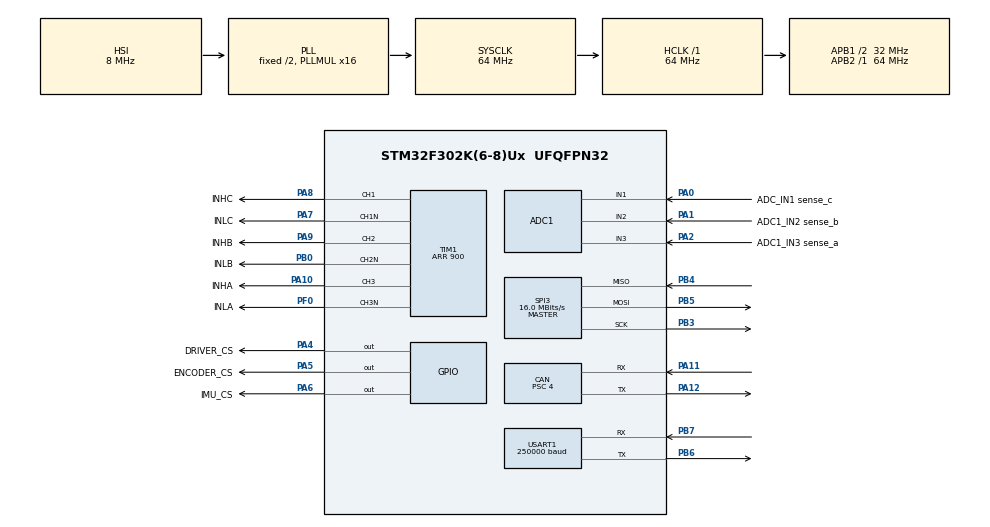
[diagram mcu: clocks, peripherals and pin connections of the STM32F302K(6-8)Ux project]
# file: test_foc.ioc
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ADC1.Channel-3\#ChannelRegularConversion=ADC_CHANNEL_1
ADC1.ContinuousConvMode=DISABLE
ADC1.DMAContinuousRequests=DISABLE
ADC1.EOCSelection=ADC_EOC_SEQ_CONV
ADC1.EnableInjectedConversion=ENABLE
ADC1.EnableRegularConversion=ENABLE
ADC1.ExternalTrigConv=ADC_SOFTWARE_START
ADC1.ExternalTrigConvEdge=ADC_EXTERNALTRIGCONVEDGE_RISING
ADC1.ExternalTrigInjecConv=ADC_EXTERNALTRIGINJECCONV_T1_CC4
ADC1.ExternalTrigInjecConvEdge=ADC_EXTERNALTRIGINJECCONV_EDGE_RISING
ADC1.InjNumberOfConversion=3
ADC1.InjectedChannel-4\#ChannelInjectedConversion=ADC_CHANNEL_1
ADC1.InjectedChannel-5\#ChannelInjectedConversion=ADC_CHANNEL_2
ADC1.InjectedChannel-6\#ChannelInjectedConversion=ADC_CHANNEL_3
ADC1.InjectedOffset-4\#ChannelInjectedConversion=0
ADC1.InjectedOffset-5\#ChannelInjectedConversion=0
ADC1.InjectedOffset-6\#ChannelInjectedConversion=0
ADC1.InjectedOffsetNumber-4\#ChannelInjectedConversion=ADC_OFFSET_NONE
ADC1.InjectedOffsetNumber-5\#ChannelInjectedConversion=ADC_OFFSET_NONE
ADC1.InjectedOffsetNumber-6\#ChannelInjectedConversion=ADC_OFFSET_NONE
ADC1.InjectedRank-4\#ChannelInjectedConversion=1
ADC1.InjectedRank-5\#ChannelInjectedConversion=2
ADC1.InjectedRank-6\#ChannelInjectedConversion=3
ADC1.InjectedSamplingTime-4\#ChannelInjectedConversion=ADC_SAMPLETIME_19CYCLES_5
ADC1.InjectedSamplingTime-5\#ChannelInjectedConversion=ADC_SAMPLETIME_19CYCLES_5
ADC1.InjectedSamplingTime-6\#ChannelInjectedConversion=ADC_SAMPLETIME_19CYCLES_5
ADC1.InjectedSamplingTimeOPAMP-4\#ChannelInjectedConversion=ADC_SAMPLETIME_7CYCLES_5
ADC1.InjectedSamplingTimeOPAMP-5\#ChannelInjectedConversion=ADC_SAMPLETIME_7CYCLES_5
ADC1.InjectedSamplingTimeOPAMP-6\#ChannelInjectedConversion=ADC_SAMPLETIME_7CYCLES_5
ADC1.NbrOfConversionFlag=1
ADC1.Offset-3\#ChannelRegularConversion=0
ADC1.OffsetNumber-3\#ChannelRegularConversion=ADC_OFFSET_NONE
ADC1.Rank-3\#ChannelRegularConversion=1
ADC1.Rank1_Channel=ADC_CHANNEL_1
ADC1.Rank2_Channel=ADC_CHANNEL_2
ADC1.Rank3_Channel=ADC_CHANNEL_3
ADC1.SamplingTime-3\#ChannelRegularConversion=ADC_SAMPLETIME_1CYCLE_5
ADC1.SubFamily=STM32F302x8
ADC1.master=1
CAN.BS1=CAN_BS1_15TQ
CAN.BS2=CAN_BS2_2TQ
CAN.CalculateBaudRate=444444
CAN.CalculateTimeBit=2250
CAN.CalculateTimeQuantum=125.0
CAN.NART=ENABLE
CAN.Prescaler=4
Dma.ADC1.0.Direction=DMA_PERIPH_TO_MEMORY
Dma.ADC1.0.Instance=DMA1_Channel1
Dma.ADC1.0.MemDataAlignment=DMA_MDATAALIGN_HALFWORD
Dma.ADC1.0.MemInc=DMA_MINC_ENABLE
Dma.ADC1.0.Mode=DMA_CIRCULAR
Dma.ADC1.0.PeriphDataAlignment=DMA_PDATAALIGN_HALFWORD
Dma.ADC1.0.PeriphInc=DMA_PINC_DISABLE
Dma.ADC1.0.Priority=DMA_PRIORITY_LOW
Dma.Request0=ADC1
Mcu.Family=STM32F3
Mcu.Name=STM32F302K(6-8)Ux
Mcu.Package=UFQFPN32
NVIC.ADC1_IRQn=true\:0\:0\:false\:false\:true\:true\:true\:true
NVIC.DMA1_Channel1_IRQn=true\:0\:0\:false\:false\:true\:false\:true\:true
NVIC.PriorityGroup=NVIC_PRIORITYGROUP_4
NVIC.TIM6_DAC_IRQn=true\:0\:0\:false\:false\:true\:true\:true\:true
NVIC.USB_LP_CAN_RX0_IRQn=true\:0\:0\:false\:false\:true\:true\:true\:true
PA0.GPIO_Label=ADC_IN1 sense_c
PA0.Mode=IN1-Single-Ended
PA0.Signal=ADC1_IN1
PA1.GPIO_Label=ADC1_IN2 sense_b
PA1.Mode=IN2-Single-Ended
PA1.Signal=ADC1_IN2
PA10.GPIO_Label=INHA
PA10.Signal=S_TIM1_CH3
PA11.Mode=CAN_Activate
PA11.Signal=CAN_RX
PA12.Mode=CAN_Activate
PA12.Signal=CAN_TX
PA2.GPIO_Label=ADC1_IN3 sense_a
PA2.Mode=IN3-Single-Ended
PA2.Signal=ADC1_IN3
PA4.GPIO_Label=DRIVER_CS
PA4.GPIO_Speed=GPIO_SPEED_FREQ_HIGH
PA4.PinState=GPIO_PIN_SET
PA4.Signal=GPIO_Output
PA5.GPIO_Label=ENCODER_CS
PA5.GPIO_ModeDefaultOutputPP=GPIO_MODE_OUTPUT_PP
PA5.GPIO_Speed=GPIO_SPEED_FREQ_HIGH
PA5.PinState=GPIO_PIN_SET
PA5.Signal=GPIO_Output
PA6.GPIO_Label=IMU_CS
PA6.GPIO_Speed=GPIO_SPEED_FREQ_HIGH
PA6.PinState=GPIO_PIN_SET
PA6.Signal=GPIO_Output
PA7.GPIO_Label=INLC
PA7.Mode=PWM Generation1 CH1 CH1N
PA7.Signal=TIM1_CH1N
PA8.GPIO_Label=INHC
PA8.Signal=S_TIM1_CH1
PA9.GPIO_Label=INHB
PA9.Signal=S_TIM1_CH2
PB0.GPIO_Label=INLB
PB0.Mode=PWM Generation2 CH2 CH2N
PB0.Signal=TIM1_CH2N
PB3.Mode=Full_Duplex_Master
PB3.Signal=SPI3_SCK
PB4.Mode=Full_Duplex_Master
PB4.Signal=SPI3_MISO
PB5.Mode=Full_Duplex_Master
PB5.Signal=SPI3_MOSI
PB6.Mode=Asynchronous
PB6.Signal=USART1_TX
PB7.Mode=Asynchronous
PB7.Signal=USART1_RX
PF0-OSC_IN.GPIO_Label=INLA
PF0-OSC_IN.Mode=PWM Generation3 CH3 CH3N
PF0-OSC_IN.Signal=TIM1_CH3N
ProjectManager.HeapSize=0x200
ProjectManager.StackSize=0x400
ProjectManager.TargetToolchain=CMake
RCC.AHBFreq_Value=64000000
RCC.APB1CLKDivider=RCC_HCLK_DIV2
RCC.APB1Freq_Value=32000000
RCC.APB1TimFreq_Value=64000000
RCC.APB2Freq_Value=64000000
RCC.APB2TimFreq_Value=64000000
RCC.CortexFreq_Value=64000000
RCC.HCLKFreq_Value=64000000
RCC.HSE_VALUE=8000000
RCC.HSI_VALUE=8000000
RCC.PLLMUL=RCC_PLL_MUL16
RCC.SYSCLKFreq_VALUE=64000000
RCC.SYSCLKSourceVirtual=RCC_SYSCLKSOURCE_PLLCLK
RCC.USBFreq_Value=64000000
SH.S_TIM1_CH1.0=TIM1_CH1,PWM Generation1 CH1 CH1N
SH.S_TIM1_CH2.0=TIM1_CH2,PWM Generation2 CH2 CH2N
SH.S_TIM1_CH3.0=TIM1_CH3,PWM Generation3 CH3 CH3N
SPI3.BaudRatePrescaler=SPI_BAUDRATEPRESCALER_2
SPI3.CLKPhase=SPI_PHASE_2EDGE
SPI3.CLKPolarity=SPI_POLARITY_HIGH
SPI3.CalculateBaudRate=16.0 MBits/s
SPI3.DataSize=SPI_DATASIZE_8BIT
SPI3.Direction=SPI_DIRECTION_2LINES
SPI3.Mode=SPI_MODE_MASTER
SPI3.VirtualType=VM_MASTER
TIM1.AutoReloadPreload=TIM_AUTORELOAD_PRELOAD_ENABLE
TIM1.Channel-PWM\ Generation1\ CH1\ CH1N=TIM_CHANNEL_1
TIM1.Channel-PWM\ Generation2\ CH2\ CH2N=TIM_CHANNEL_2
TIM1.Channel-PWM\ Generation3\ CH3\ CH3N=TIM_CHANNEL_3
TIM1.Channel-PWM\ Generation4\ No\ Output=TIM_CHANNEL_4
TIM1.CounterMode=TIM_COUNTERMODE_CENTERALIGNED1
TIM1.DeadTime=100
TIM1.OffStateIDLEMode=TIM_OSSI_ENABLE
TIM1.OffStateRunMode=TIM_OSSR_ENABLE
TIM1.Period=900
TIM6.Period=999
TIM6.Prescaler=31
USART1.BaudRate=250000
USART1.VirtualMode-Asynchronous=VM_ASYNC
VP_CRC_VS_CRC.Mode=CRC_Activate
VP_TIM1_VS_ClockSourceINT.Mode=Internal
VP_TIM1_VS_no_output4.Mode=PWM Generation4 No Output
VP_TIM6_VS_ClockSourceINT.Mode=Enable_Timer
board=custom

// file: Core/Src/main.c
/* USER CODE BEGIN Header */
/**
  ******************************************************************************
  * @file           : main.c
  * @brief          : Main program body
  ******************************************************************************
  * @attention
  *
  * Copyright (c) 2026 STMicroelectronics.
  * All rights reserved.
  *
  * This software is licensed under terms that can be found in the LICENSE file
  * in the root directory of this software component.
  * If no LICENSE file comes with this software, it is provided AS-IS.
  *
  ******************************************************************************
  */
/* USER CODE END Header */
#include "main.h"

/* USER CODE BEGIN Includes */
#include "stm32f3xx_hal.h"
#include "string.h"
#include <stdio.h>
#include <inttypes.h>

#include <math.h>

#include "encoder.h"
#include "driver.h"
#include "foc.h"

#include "debug_utils.h"
#include "pi_controller.h"

#include "communication.h"
#include "commands.h"

#include "config.h"

/* USER CODE END Includes */

/* USER CODE BEGIN PTD */
static const drv8316_csa_gain_t g_drv_gain = DRV8316_CSA_GAIN_0V60_PER_A;

static driver_current_offsets_t g_current_offsets = {0};
static driver_phase_currents_t g_phase_currents = {0};

/* USER CODE END PTD */

/* USER CODE BEGIN PD */
#define ENC_CS_GPIO_Port GPIOA
#define ENC_CS_Pin       GPIO_PIN_5
// #define V_BUS_NOMINAL 1.0f
/* USER CODE END PD */

ADC_HandleTypeDef hadc1;
DMA_HandleTypeDef hdma_adc1;

CAN_HandleTypeDef hcan;

CRC_HandleTypeDef hcrc;

SPI_HandleTypeDef hspi3;

TIM_HandleTypeDef htim1;
TIM_HandleTypeDef htim6;

UART_HandleTypeDef huart1;

void SystemClock_Config(void);
static void MX_GPIO_Init(void);
static void MX_DMA_Init(void);
static void MX_USART1_UART_Init(void);
static void MX_CAN_Init(void);
static void MX_CRC_Init(void);
static void MX_TIM1_Init(void);
static void MX_SPI3_Init(void);
static void MX_ADC1_Init(void);
static void MX_TIM6_Init(void);

/* USER CODE BEGIN 0 */

volatile uint16_t ia_raw, ib_raw, ic_raw; // Raw ADC currents
volatile float ia, ib, ic;                // Measured currents
volatile float va, vb, vc;                // Output voltages before SVPWM

volatile config_t config; // Global config
uint32_t adc_inj_cb_count = 0;

// volatile uint32_t adc_inj_cb_count = 0;

void HAL_TIM_PeriodElapsedCallback(TIM_HandleTypeDef *htim)
{
    if (htim->Instance != TIM6) return;
    // handle_communication(&config);

    adc_inj_cb_count++;
    if (config.control_state == NO_CONTROL) return;

    const float dt = 1.0f/2000.0f;

    // ---- < Velocity PI control > ----
    if (config.control_state >= VELOCITY_CONTROL){
      float velocity = get_angular_velocity(&config.encoder);
      float error_w = config.angular_velocity_target - velocity;
      config.torque_current_target = pi_update(&config.regulators.pi_angular_velocity, error_w, dt);
    }

    // ---- < Position PID control > -----
    if (config.control_state >= POSITION_CONTROL){
      float position = encoder_get_turns(&config.encoder);
      float error_pos = config.position_target - position;
      config.angular_velocity_target = pid_update(&config.regulators.pid_position, error_pos, dt);
    }
}

void HAL_ADCEx_InjectedConvCpltCallback(ADC_HandleTypeDef *hadc) {
    // Current FOC control
    if (hadc->Instance != ADC1) return;
    // adc_inj_cb_count++;
    // ----- <Read currents from ADC> ------
    ic_raw = (uint16_t)HAL_ADCEx_InjectedGetValue(hadc, ADC_INJECTED_RANK_1);
    ib_raw = (uint16_t)HAL_ADCEx_InjectedGetValue(hadc, ADC_INJECTED_RANK_2);
    ia_raw = (uint16_t)HAL_ADCEx_InjectedGetValue(hadc, ADC_INJECTED_RANK_3);
    driver_phase_currents_from_adc(&g_phase_currents,
        ia_raw,
        ib_raw,
        ic_raw,
        &g_current_offsets,
        g_drv_gain);

        ia = g_phase_currents.a;
        ib = g_phase_currents.b;
        ic = g_phase_currents.c;
    // ----- <Read currents from ADC> ------

    update_encoder(&config.encoder);

    if (config.control_state >= CURRENT_CONTROL){
      // FOC control loop
      float theta_e = config.encoder.electrical_angle;
      foc_compute_voltages(config.flux_current_target, config.torque_current_target, // reference currents for PI regulator
                    &theta_e, // measured electric angle
                        (float*)&ia, (float*)&ib, (float*)&ic, // measured input current
                        &va, &vb, &vc, // calculated output voltage
                      &config.regulators.pi_d_current_axis, &config.regulators.pi_q_current_axis); // PI config.regulators

      // SVPWM control
      float va_svpwm, vb_svpwm, vc_svpwm;
      svpwm(&va, &vb, &vc, &va_svpwm, &vb_svpwm, &vc_svpwm);

      float du = 0.5f + va_svpwm / V_BUS_NOMINAL;
      float dv = 0.5f + vb_svpwm / V_BUS_NOMINAL;
      float dw = 0.5f + vc_svpwm / V_BUS_NOMINAL;

      pwm_set(du, dv, dw);
    }
  }

  // ------- < CAN COMUNICATION > -----------
  void HAL_CAN_RxFifo0MsgPendingCallback(CAN_HandleTypeDef *hcan){
      communication_rx_fifo0_pending_callback(hcan);
      handle_communication(&config);
    }
  // ------- < / CAN COMUNICATION > -----------

char buffer[128];

/* USER CODE END 0 */

int main(void)
{

  /* MCU Configuration--------------------------------------------------------*/

  /* Reset of all peripherals, Initializes the Flash interface and the Systick. */
  HAL_Init();

  /* Configure the system clock */
  SystemClock_Config();

  /* Initialize all configured peripherals */
  MX_GPIO_Init();
  MX_DMA_Init();
  MX_USART1_UART_Init();
  MX_CAN_Init();
  MX_CRC_Init();
  MX_TIM1_Init();
  MX_SPI3_Init();
  MX_ADC1_Init();
  MX_TIM6_Init();
  /* USER CODE BEGIN 2 */

  config = init_config();  // initialize config

  init_sin_table();
  drv8316_init(g_drv_gain);
  HAL_Delay(300);
  config.encoder = init_encoder(MOTOR_MAGNETIC_PAIRS, ENCODER_ELECTRICAL_OFFSET, ENCODER_INVERT_DIR);
  mt6835_init();

  // ------ <Calibrate ADC> -----
  if (HAL_ADCEx_Calibration_Start(&hadc1, ADC_SINGLE_ENDED) != HAL_OK) {
    Error_Handler();
  }

  TIM1->CCR4 = TIM1->ARR / 2;

  pwm_init();
  HAL_TIM_PWM_Start(&htim1, TIM_CHANNEL_4);

  // TIM1
  __HAL_TIM_MOE_ENABLE(&htim1);
  if (HAL_ADCEx_InjectedStart_IT(&hadc1) != HAL_OK) {
    Error_Handler();
  }

  // ----- <Calibrate current sensor offsets> -----
  pwm_set(0.5f, 0.5f, 0.5f);
  HAL_Delay(20);
  if (driver_current_calibrate_offsets(&g_current_offsets,
    &ia_raw,
    &ib_raw,
    &ic_raw,
    512,
    1) != HAL_OK) {
      Error_Handler();
    }
  // ----- </Calibrate current sensor offsets> -----

  mt6835_init();
  HAL_Delay(20);
  calibrate_electrical_offset(&config.encoder);

  if (HAL_TIM_Base_Start_IT(&htim6) != HAL_OK) {
    Error_Handler();
  }

  // mt6835_init();
  HAL_Delay(20);
  // config.position_target = encoder_get_turns(&config.encoder);
  config.position_target = 0.0f;
  // config.control_state = POSITION_CONTROL;
  config.control_state = NO_CONTROL;
  HAL_Delay(500);

  // ---- < Can communication > ----
  communication_init(&hcan);
  communication_start();
  // ---- < /Can communication > ----

  /* USER CODE END 2 */

  /* Infinite loop */
  /* USER CODE BEGIN WHILE */

  static uint32_t last_ms = 0;
  static uint32_t last_count = 0;
  while (1){
    // handle_communication(&config);

    // sprintf(buffer, "%d\r\n", config.encoder.current_raw_value);
    sprintf(buffer, "%f %f\r\n", config.angular_velocity_target, get_angular_velocity(&config.encoder));
    print(buffer);
    // HAL_Delay(10);

    // Timer frequency check
    // uint32_t now = HAL_GetTick();
    // if (now - last_ms >= 1000) {
    //     uint32_t cnt = adc_inj_cb_count;
    //     uint32_t diff = cnt - last_count;

    //     sprintf(buffer, "ADC inj cb freq: %lu Hz\r\n", (unsigned long)diff);
    //     print(buffer);

    //     last_count = cnt;
    //     last_ms = now;
    // }

  }

    /* USER CODE END WHILE */

}

void SystemClock_Config(void)
{
  RCC_OscInitTypeDef RCC_OscInitStruct = {0};
  RCC_ClkInitTypeDef RCC_ClkInitStruct = {0};
  RCC_PeriphCLKInitTypeDef PeriphClkInit = {0};

  /** Initializes the RCC Oscillators according to the specified parameters
  * in the RCC_OscInitTypeDef structure.
  */
  RCC_OscInitStruct.OscillatorType = RCC_OSCILLATORTYPE_HSI;
  RCC_OscInitStruct.HSIState = RCC_HSI_ON;
  RCC_OscInitStruct.HSICalibrationValue = RCC_HSICALIBRATION_DEFAULT;
  RCC_OscInitStruct.PLL.PLLState = RCC_PLL_ON;
  RCC_OscInitStruct.PLL.PLLSource = RCC_PLLSOURCE_HSI;
  RCC_OscInitStruct.PLL.PLLMUL = RCC_PLL_MUL16;
  if (HAL_RCC_OscConfig(&RCC_OscInitStruct) != HAL_OK)
  {
    Error_Handler();
  }

  /** Initializes the CPU, AHB and APB buses clocks
  */
  RCC_ClkInitStruct.ClockType = RCC_CLOCKTYPE_HCLK|RCC_CLOCKTYPE_SYSCLK
                              |RCC_CLOCKTYPE_PCLK1|RCC_CLOCKTYPE_PCLK2;
  RCC_ClkInitStruct.SYSCLKSource = RCC_SYSCLKSOURCE_PLLCLK;
  RCC_ClkInitStruct.AHBCLKDivider = RCC_SYSCLK_DIV1;
  RCC_ClkInitStruct.APB1CLKDivider = RCC_HCLK_DIV2;
  RCC_ClkInitStruct.APB2CLKDivider = RCC_HCLK_DIV1;

  if (HAL_RCC_ClockConfig(&RCC_ClkInitStruct, FLASH_LATENCY_2) != HAL_OK)
  {
    Error_Handler();
  }
  PeriphClkInit.PeriphClockSelection = RCC_PERIPHCLK_USART1|RCC_PERIPHCLK_TIM1
                              |RCC_PERIPHCLK_ADC1;
  PeriphClkInit.Usart1ClockSelection = RCC_USART1CLKSOURCE_PCLK1;
  PeriphClkInit.Tim1ClockSelection = RCC_TIM1CLK_HCLK;
  PeriphClkInit.Adc1ClockSelection = RCC_ADC1PLLCLK_DIV1;

  if (HAL_RCCEx_PeriphCLKConfig(&PeriphClkInit) != HAL_OK)
  {
    Error_Handler();
  }
}

static void MX_ADC1_Init(void)
{

  ADC_ChannelConfTypeDef sConfig = {0};
  ADC_InjectionConfTypeDef sConfigInjected = {0};

  /** Common config
  */
  hadc1.Instance = ADC1;
  hadc1.Init.ClockPrescaler = ADC_CLOCK_ASYNC_DIV1;
  hadc1.Init.Resolution = ADC_RESOLUTION_12B;
  hadc1.Init.ScanConvMode = ADC_SCAN_ENABLE;
  hadc1.Init.ContinuousConvMode = DISABLE;
  hadc1.Init.DiscontinuousConvMode = DISABLE;
  hadc1.Init.ExternalTrigConvEdge = ADC_EXTERNALTRIGCONVEDGE_RISING;
  hadc1.Init.ExternalTrigConv = ADC_SOFTWARE_START;
  hadc1.Init.DataAlign = ADC_DATAALIGN_RIGHT;
  hadc1.Init.NbrOfConversion = 1;
  hadc1.Init.DMAContinuousRequests = DISABLE;
  hadc1.Init.EOCSelection = ADC_EOC_SEQ_CONV;
  hadc1.Init.LowPowerAutoWait = DISABLE;
  hadc1.Init.Overrun = ADC_OVR_DATA_OVERWRITTEN;
  if (HAL_ADC_Init(&hadc1) != HAL_OK)
  {
    Error_Handler();
  }

  /** Configure Regular Channel
  */
  sConfig.Channel = ADC_CHANNEL_1;
  sConfig.Rank = ADC_REGULAR_RANK_1;
  sConfig.SingleDiff = ADC_SINGLE_ENDED;
  sConfig.SamplingTime = ADC_SAMPLETIME_1CYCLE_5;
  sConfig.OffsetNumber = ADC_OFFSET_NONE;
  sConfig.Offset = 0;
  if (HAL_ADC_ConfigChannel(&hadc1, &sConfig) != HAL_OK)
  {
    Error_Handler();
  }

  /** Configure Injected Channel
  */
  sConfigInjected.InjectedChannel = ADC_CHANNEL_1;
  sConfigInjected.InjectedRank = ADC_INJECTED_RANK_1;
  sConfigInjected.InjectedSingleDiff = ADC_SINGLE_ENDED;
  sConfigInjected.InjectedNbrOfConversion = 3;
  sConfigInjected.InjectedSamplingTime = ADC_SAMPLETIME_19CYCLES_5;
  sConfigInjected.ExternalTrigInjecConvEdge = ADC_EXTERNALTRIGINJECCONV_EDGE_RISING;
  sConfigInjected.ExternalTrigInjecConv = ADC_EXTERNALTRIGINJECCONV_T1_CC4;
  sConfigInjected.AutoInjectedConv = DISABLE;
  sConfigInjected.InjectedDiscontinuousConvMode = DISABLE;
  sConfigInjected.QueueInjectedContext = DISABLE;
  sConfigInjected.InjectedOffset = 0;
  sConfigInjected.InjectedOffsetNumber = ADC_OFFSET_NONE;
  if (HAL_ADCEx_InjectedConfigChannel(&hadc1, &sConfigInjected) != HAL_OK)
  {
    Error_Handler();
  }

  /** Configure Injected Channel
  */
  sConfigInjected.InjectedChannel = ADC_CHANNEL_2;
  sConfigInjected.InjectedRank = ADC_INJECTED_RANK_2;
  if (HAL_ADCEx_InjectedConfigChannel(&hadc1, &sConfigInjected) != HAL_OK)
  {
    Error_Handler();
  }

  /** Configure Injected Channel
  */
  sConfigInjected.InjectedChannel = ADC_CHANNEL_3;
  sConfigInjected.InjectedRank = ADC_INJECTED_RANK_3;
  if (HAL_ADCEx_InjectedConfigChannel(&hadc1, &sConfigInjected) != HAL_OK)
  {
    Error_Handler();
  }

}

static void MX_CAN_Init(void)
{

  hcan.Instance = CAN;
  hcan.Init.Prescaler = 4;
  hcan.Init.Mode = CAN_MODE_NORMAL;
  hcan.Init.SyncJumpWidth = CAN_SJW_1TQ;
  hcan.Init.TimeSeg1 = CAN_BS1_13TQ;
  hcan.Init.TimeSeg2 = CAN_BS2_2TQ;
  hcan.Init.TimeTriggeredMode = DISABLE;
  hcan.Init.AutoBusOff = DISABLE;
  hcan.Init.AutoWakeUp = DISABLE;
  hcan.Init.AutoRetransmission = ENABLE;
  hcan.Init.ReceiveFifoLocked = DISABLE;
  hcan.Init.TransmitFifoPriority = DISABLE;
  if (HAL_CAN_Init(&hcan) != HAL_OK)
  {
    Error_Handler();
  }

}

static void MX_CRC_Init(void)
{

  hcrc.Instance = CRC;
  hcrc.Init.DefaultPolynomialUse = DEFAULT_POLYNOMIAL_ENABLE;
  hcrc.Init.DefaultInitValueUse = DEFAULT_INIT_VALUE_ENABLE;
  hcrc.Init.InputDataInversionMode = CRC_INPUTDATA_INVERSION_NONE;
  hcrc.Init.OutputDataInversionMode = CRC_OUTPUTDATA_INVERSION_DISABLE;
  hcrc.InputDataFormat = CRC_INPUTDATA_FORMAT_BYTES;
  if (HAL_CRC_Init(&hcrc) != HAL_OK)
  {
    Error_Handler();
  }

}

static void MX_SPI3_Init(void)
{

  /* SPI3 parameter configuration*/
  hspi3.Instance = SPI3;
  hspi3.Init.Mode = SPI_MODE_MASTER;
  hspi3.Init.Direction = SPI_DIRECTION_2LINES;
  hspi3.Init.DataSize = SPI_DATASIZE_8BIT;
  hspi3.Init.CLKPolarity = SPI_POLARITY_HIGH;
  hspi3.Init.CLKPhase = SPI_PHASE_2EDGE;
  hspi3.Init.NSS = SPI_NSS_SOFT;
  hspi3.Init.BaudRatePrescaler = SPI_BAUDRATEPRESCALER_2;
  hspi3.Init.FirstBit = SPI_FIRSTBIT_MSB;
  hspi3.Init.TIMode = SPI_TIMODE_DISABLE;
  hspi3.Init.CRCCalculation = SPI_CRCCALCULATION_DISABLE;
  hspi3.Init.CRCPolynomial = 7;
  hspi3.Init.CRCLength = SPI_CRC_LENGTH_DATASIZE;
  hspi3.Init.NSSPMode = SPI_NSS_PULSE_DISABLE;
  if (HAL_SPI_Init(&hspi3) != HAL_OK)
  {
    Error_Handler();
  }

}

static void MX_TIM1_Init(void)
{

  TIM_ClockConfigTypeDef sClockSourceConfig = {0};
  TIM_MasterConfigTypeDef sMasterConfig = {0};
  TIM_OC_InitTypeDef sConfigOC = {0};
  TIM_BreakDeadTimeConfigTypeDef sBreakDeadTimeConfig = {0};

  htim1.Instance = TIM1;
  htim1.Init.Prescaler = 0;
  htim1.Init.CounterMode = TIM_COUNTERMODE_CENTERALIGNED1;
  htim1.Init.Period = 3599;
  htim1.Init.ClockDivision = TIM_CLOCKDIVISION_DIV1;
  htim1.Init.RepetitionCounter = 0;
  htim1.Init.AutoReloadPreload = TIM_AUTORELOAD_PRELOAD_ENABLE;
  if (HAL_TIM_Base_Init(&htim1) != HAL_OK)
  {
    Error_Handler();
  }
  sClockSourceConfig.ClockSource = TIM_CLOCKSOURCE_INTERNAL;
  if (HAL_TIM_ConfigClockSource(&htim1, &sClockSourceConfig) != HAL_OK)
  {
    Error_Handler();
  }
  if (HAL_TIM_PWM_Init(&htim1) != HAL_OK)
  {
    Error_Handler();
  }
  sMasterConfig.MasterOutputTrigger = TIM_TRGO_RESET;
  sMasterConfig.MasterOutputTrigger2 = TIM_TRGO2_RESET;
  sMasterConfig.MasterSlaveMode = TIM_MASTERSLAVEMODE_DISABLE;
  if (HAL_TIMEx_MasterConfigSynchronization(&htim1, &sMasterConfig) != HAL_OK)
  {
    Error_Handler();
  }
  sConfigOC.OCMode = TIM_OCMODE_PWM1;
  sConfigOC.Pulse = 0;
  sConfigOC.OCPolarity = TIM_OCPOLARITY_HIGH;
  sConfigOC.OCNPolarity = TIM_OCNPOLARITY_HIGH;
  sConfigOC.OCFastMode = TIM_OCFAST_DISABLE;
  sConfigOC.OCIdleState = TIM_OCIDLESTATE_RESET;
  sConfigOC.OCNIdleState = TIM_OCNIDLESTATE_RESET;
  if (HAL_TIM_PWM_ConfigChannel(&htim1, &sConfigOC, TIM_CHANNEL_1) != HAL_OK)
  {
    Error_Handler();
  }
  if (HAL_TIM_PWM_ConfigChannel(&htim1, &sConfigOC, TIM_CHANNEL_2) != HAL_OK)
  {
    Error_Handler();
  }
  if (HAL_TIM_PWM_ConfigChannel(&htim1, &sConfigOC, TIM_CHANNEL_3) != HAL_OK)
  {
    Error_Handler();
  }
  if (HAL_TIM_PWM_ConfigChannel(&htim1, &sConfigOC, TIM_CHANNEL_4) != HAL_OK)
  {
    Error_Handler();
  }
  sBreakDeadTimeConfig.OffStateRunMode = TIM_OSSR_ENABLE;
  sBreakDeadTimeConfig.OffStateIDLEMode = TIM_OSSI_ENABLE;
  sBreakDeadTimeConfig.LockLevel = TIM_LOCKLEVEL_OFF;
  sBreakDeadTimeConfig.DeadTime = 100;
  sBreakDeadTimeConfig.BreakState = TIM_BREAK_DISABLE;
  sBreakDeadTimeConfig.BreakPolarity = TIM_BREAKPOLARITY_HIGH;
  sBreakDeadTimeConfig.BreakFilter = 0;
  sBreakDeadTimeConfig.Break2State = TIM_BREAK2_DISABLE;
  sBreakDeadTimeConfig.Break2Polarity = TIM_BREAK2POLARITY_HIGH;
  sBreakDeadTimeConfig.Break2Filter = 0;
  sBreakDeadTimeConfig.AutomaticOutput = TIM_AUTOMATICOUTPUT_DISABLE;
  if (HAL_TIMEx_ConfigBreakDeadTime(&htim1, &sBreakDeadTimeConfig) != HAL_OK)
  {
    Error_Handler();
  }
  HAL_TIM_MspPostInit(&htim1);

}

static void MX_TIM6_Init(void)
{

  TIM_MasterConfigTypeDef sMasterConfig = {0};

  htim6.Instance = TIM6;
  htim6.Init.Prescaler = 31;
  htim6.Init.CounterMode = TIM_COUNTERMODE_UP;
  htim6.Init.Period = 999;
  htim6.Init.AutoReloadPreload = TIM_AUTORELOAD_PRELOAD_DISABLE;
  if (HAL_TIM_Base_Init(&htim6) != HAL_OK)
  {
    Error_Handler();
  }
  sMasterConfig.MasterOutputTrigger = TIM_TRGO_RESET;
  sMasterConfig.MasterSlaveMode = TIM_MASTERSLAVEMODE_DISABLE;
  if (HAL_TIMEx_MasterConfigSynchronization(&htim6, &sMasterConfig) != HAL_OK)
  {
    Error_Handler();
  }

}

static void MX_USART1_UART_Init(void)
{

  huart1.Instance = USART1;
  huart1.Init.BaudRate = 250000;
  huart1.Init.WordLength = UART_WORDLENGTH_8B;
  huart1.Init.StopBits = UART_STOPBITS_1;
  huart1.Init.Parity = UART_PARITY_NONE;
  huart1.Init.Mode = UART_MODE_TX_RX;
  huart1.Init.HwFlowCtl = UART_HWCONTROL_NONE;
  huart1.Init.OverSampling = UART_OVERSAMPLING_16;
  huart1.Init.OneBitSampling = UART_ONE_BIT_SAMPLE_DISABLE;
  huart1.AdvancedInit.AdvFeatureInit = UART_ADVFEATURE_NO_INIT;
  if (HAL_UART_Init(&huart1) != HAL_OK)
  {
    Error_Handler();
  }

}

static void MX_DMA_Init(void)
{

  /* DMA controller clock enable */
  __HAL_RCC_DMA1_CLK_ENABLE();

  /* DMA interrupt init */
  /* DMA1_Channel1_IRQn interrupt configuration */
  HAL_NVIC_SetPriority(DMA1_Channel1_IRQn, 0, 0);
  HAL_NVIC_EnableIRQ(DMA1_Channel1_IRQn);

}

static void MX_GPIO_Init(void)
{
  GPIO_InitTypeDef GPIO_InitStruct = {0};

  /* GPIO Ports Clock Enable */
  __HAL_RCC_GPIOF_CLK_ENABLE();
  __HAL_RCC_GPIOA_CLK_ENABLE();
  __HAL_RCC_GPIOB_CLK_ENABLE();

  /*Configure GPIO pin Output Level */
  HAL_GPIO_WritePin(GPIOA, DRIVER_CS_Pin|ENCODER_CS_Pin|IMU_CS_Pin, GPIO_PIN_SET);

  /*Configure GPIO pin Output Level */
  HAL_GPIO_WritePin(PA15_LOW_GPIO_Port, PA15_LOW_Pin, GPIO_PIN_RESET);

  /*Configure GPIO pins : DRIVER_CS_Pin ENCODER_CS_Pin IMU_CS_Pin */
  GPIO_InitStruct.Pin = DRIVER_CS_Pin|ENCODER_CS_Pin|IMU_CS_Pin;
  GPIO_InitStruct.Mode = GPIO_MODE_OUTPUT_PP;
  GPIO_InitStruct.Pull = GPIO_NOPULL;
  GPIO_InitStruct.Speed = GPIO_SPEED_FREQ_HIGH;
  HAL_GPIO_Init(GPIOA, &GPIO_InitStruct);

  /*Configure GPIO pin : PA15_LOW_Pin */
  GPIO_InitStruct.Pin = PA15_LOW_Pin;
  GPIO_InitStruct.Mode = GPIO_MODE_OUTPUT_PP;
  GPIO_InitStruct.Pull = GPIO_NOPULL;
  GPIO_InitStruct.Speed = GPIO_SPEED_FREQ_LOW;
  HAL_GPIO_Init(PA15_LOW_GPIO_Port, &GPIO_InitStruct);

}

void Error_Handler(void)
{
  __disable_irq();
  while (1)
  {
  }
}
